AUTOSAR XML (schema 00049)
standard types defined: boolean, float32, uint16, uint8, boolean_CompuMethod, boolean_DataConstr, float32_DataConstr, uint16_DataConstr, uint8_DataConstr
package /ComponentTypes
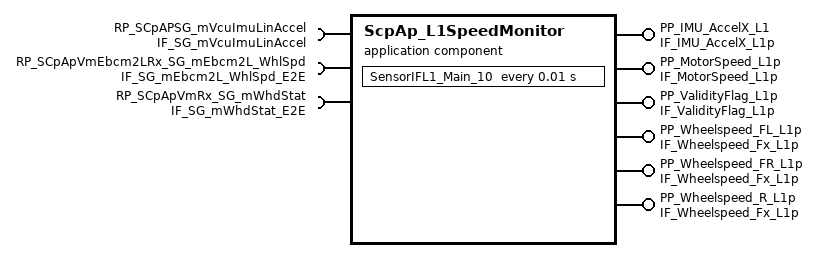
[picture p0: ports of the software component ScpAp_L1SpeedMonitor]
  application sw component type ScpAp_L1SpeedMonitor
    6 x provide port:
      PP_IMU_AccelX_L1: nonqueued-sender-com-spec{data-element=IF_IMU_AccelX_L1p, init-value=0}, provided-interface=IF_IMU_AccelX_L1p
      PP_MotorSpeed_L1p: nonqueued-sender-com-spec{data-element=IF_MotorSpeed_L1p, init-value=0}, provided-interface=IF_MotorSpeed_L1p
      PP_ValidityFlag_L1p: nonqueued-sender-com-spec{data-element=IF_ValidityFlag_L1p, init-value=fields=[Motor_RPM_Valid_Flg:0, WSS_FR_Valid_Flg:0, WSS_FL_Valid_Flg:0, WSS_R_Valid_Flg:0, IMU_AccelX_Valid_Flg:0, SensorStuck_Valid_Flg:0]}, provided-interface=IF_ValidityFlag_L1p
      PP_Wheelspeed_FL_L1p: nonqueued-sender-com-spec=data-element=IF_Wheelspeed_Fx_L1p, provided-interface=IF_Wheelspeed_Fx_L1p
      PP_Wheelspeed_FR_L1p: nonqueued-sender-com-spec=data-element=IF_Wheelspeed_Fx_L1p, provided-interface=IF_Wheelspeed_Fx_L1p
      PP_Wheelspeed_R_L1p: nonqueued-sender-com-spec=data-element=IF_Wheelspeed_Fx_L1p, provided-interface=IF_Wheelspeed_Fx_L1p
    require port RP_SCpAPSG_mVcuImuLinAccel: nonqueued-receiver-com-spec{data-element=SG_mVcuImuLinAccel_VDP, handle-out-of-range=DEFAULT, filter=data-filter-type=ALWAYS, init-value=fields=[MsgCntr_ImuLin:0, MsgCrc_ImuLin:0, X_Accel:0, Y_Accel:0, Z_Accel:0]}, required-interface=IF_SG_mVcuImuLinAccel
    require port RP_SCpApVmEbcm2LRx_SG_mEbcm2L_WhlSpd: nonqueued-receiver-com-spec{data-element=SG_mEbcm2L_WhlSpd, handle-out-of-range=DEFAULT, filter=data-filter-type=ALWAYS, init-value=fields=[MsgCntr_mEbcm2L_WhlSpd:0, MsgCrc_mEbcm2L_WhlSpd:0, WhlSpdFL:0, WhlSpdFR:0, WhlSpdR:0, CanVm7FFltCod:0]}, required-interface=IF_SG_mEbcm2L_WhlSpd_E2E
    require port RP_SCpApVmRx_SG_mWhdStat: nonqueued-receiver-com-spec{data-element=SG_mWhdStat, handle-out-of-range=DEFAULT, filter=data-filter-type=ALWAYS, init-value=fields=[HwEnblStat:0, MsgCntr_mWhdStat:0, MsgCrc_mWhdStat:0, MtrSpd:0, MtrTrqEst:0, MvCurrEst:0, MvVolt:0, TrqEnblStat:0, CanVm64FltCod:0]}, required-interface=IF_SG_mWhdStat_E2E
    behavior ScpAp_L1SpeedMonitor_InternalBehavior: handle-termination-and-restart=NO-SUPPORT
      timing event TMT_SensorIF_L1_Main: start-on-event=SensorIFL1_Main_10, period=0.01
      runnable SensorIFL1_Main_10
        data-receive-point-by-arguments:
          access REC_RP_SCpAPSG_mVcuImuLinAccel_SG_mVcuImuLinAccel_VDP: accessed-variable=RP_SCpAPSG_mVcuImuLinAccel.SG_mVcuImuLinAccel_VDP
          access REC_RP_SCpApVmEbcm2LRx_SG_mEbcm2L_WhlSpd_SG_mEbcm2L_WhlSpd: accessed-variable=RP_SCpApVmEbcm2LRx_SG_mEbcm2L_WhlSpd.SG_mEbcm2L_WhlSpd
          access REC_RP_SCpApVmRx_SG_mWhdStat_SG_mWhdStat: accessed-variable=RP_SCpApVmRx_SG_mWhdStat.SG_mWhdStat
        data-send-points:
          6 x access:
            SEND_PP_ScpAp_IMU_AccelX_L1_Element: accessed-variable=PP_IMU_AccelX_L1.IF_IMU_AccelX_L1p
            SEND_PP_ScpAp_MotorSpeed_L1p_Element: accessed-variable=PP_MotorSpeed_L1p.IF_MotorSpeed_L1p
            SEND_PP_ScpAp_ValidityFlag_L1p_IF_ValidityFlag_L1p: accessed-variable=PP_ValidityFlag_L1p.IF_ValidityFlag_L1p
            SEND_PP_ScpAp_Wheelspeed_FL_L1p_Element: accessed-variable=PP_Wheelspeed_FL_L1p.IF_Wheelspeed_Fx_L1p
            SEND_PP_Wheelspeed_FR_L1p_IF_Wheelspeed_Fx_L1p: accessed-variable=PP_Wheelspeed_FR_L1p.IF_Wheelspeed_Fx_L1p
            SEND_PP_Wheelspeed_R_L1p_IF_Wheelspeed_Fx_L1p: accessed-variable=PP_Wheelspeed_R_L1p.IF_Wheelspeed_Fx_L1p
  swc implementation ScpAp_L1SpeedMonitor_Implementation: behavior=ScpAp_L1SpeedMonitor_InternalBehavior
    code-descriptors:
      code Default: artifact-descriptors=autosar-engineering-object={short-label=Default, category=SWSRC}
package /DataTypes
  4 x impl type, all with category=STRUCTURE:
    IF_ValidityFlag_L1p_IDT: sw-calibration-access=READ-ONLY, type-emitter=RTE
      6 x element, all with category=VALUE, base-type=boolean, sw-calibration-access=READ-ONLY:
        Motor_RPM_Valid_Flg
        WSS_FR_Valid_Flg
        WSS_FL_Valid_Flg
        WSS_R_Valid_Flg
        IMU_AccelX_Valid_Flg
        SensorStuck_Valid_Flg
    SG_mEbcm2L_WhlSpd_IDT_E2E
      6 x element, all with category=TYPE_REFERENCE:
        MsgCntr_mEbcm2L_WhlSpd: range raw 0..15, implementation-data-type=uint8
        MsgCrc_mEbcm2L_WhlSpd: range raw 0..255, implementation-data-type=uint8
        WhlSpdFL: range raw -2048..2047, implementation-data-type=float32
        WhlSpdFR: range raw -2048..2047, implementation-data-type=float32
        WhlSpdR: range raw -2048..2047, implementation-data-type=float32
        CanVm7FFltCod: implementation-data-type=uint8
    SG_mVcuImuLinAccel_IDT
      5 x element, all with category=TYPE_REFERENCE:
        MsgCntr_ImuLin: range raw 0..15, implementation-data-type=uint8
        MsgCrc_ImuLin: range raw 0..255, implementation-data-type=uint8
        X_Accel: range raw -32768..32767, implementation-data-type=float32
        Y_Accel: range raw -32768..32767, implementation-data-type=float32
        Z_Accel: range raw -32768..32767, implementation-data-type=float32
    SG_mWhdStat_IDT_E2E
      9 x element, all with category=TYPE_REFERENCE:
        HwEnblStat: range raw 0..1, implementation-data-type=boolean
        MsgCntr_mWhdStat: range raw 0..15, implementation-data-type=uint8
        MsgCrc_mWhdStat: range raw 0..255, implementation-data-type=uint8
        MtrSpd: range raw -2048..2047, implementation-data-type=float32
        MtrTrqEst: range raw -2048..2047, implementation-data-type=float32
        MvCurrEst: range raw -2048..2047, implementation-data-type=float32
        MvVolt: range raw 0..4095, implementation-data-type=float32
        TrqEnblStat: range raw 0..1, implementation-data-type=boolean
        CanVm64FltCod: implementation-data-type=uint8
package /PortInterfaces
  7 x sender receiver interface:
    IF_IMU_AccelX_L1p: invalidation-policy{data-element=IF_IMU_AccelX_L1p, handle-invalid=DONT-INVALIDATE}
      data IF_IMU_AccelX_L1p: type=float32
    IF_MotorSpeed_L1p: invalidation-policy{data-element=IF_MotorSpeed_L1p, handle-invalid=DONT-INVALIDATE}
      data IF_MotorSpeed_L1p: type=uint8
    IF_SG_mEbcm2L_WhlSpd_E2E: invalidation-policy{data-element=SG_mEbcm2L_WhlSpd, handle-invalid=DONT-INVALIDATE}
      data SG_mEbcm2L_WhlSpd: category=STRUCTURE, type=SG_mEbcm2L_WhlSpd_IDT_E2E
    IF_SG_mVcuImuLinAccel: invalidation-policy{data-element=SG_mVcuImuLinAccel_VDP, handle-invalid=DONT-INVALIDATE}
      data SG_mVcuImuLinAccel_VDP: category=STRUCTURE, type=SG_mVcuImuLinAccel_IDT
    IF_SG_mWhdStat_E2E: invalidation-policy{data-element=SG_mWhdStat, handle-invalid=DONT-INVALIDATE}
      data SG_mWhdStat: category=STRUCTURE, type=SG_mWhdStat_IDT_E2E
    IF_ValidityFlag_L1p: invalidation-policy{data-element=IF_ValidityFlag_L1p, handle-invalid=DONT-INVALIDATE}
      data IF_ValidityFlag_L1p: type=IF_ValidityFlag_L1p_IDT
    IF_Wheelspeed_Fx_L1p: invalidation-policy{data-element=IF_Wheelspeed_Fx_L1p, handle-invalid=DONT-INVALIDATE}
      data IF_Wheelspeed_Fx_L1p: type=uint16
